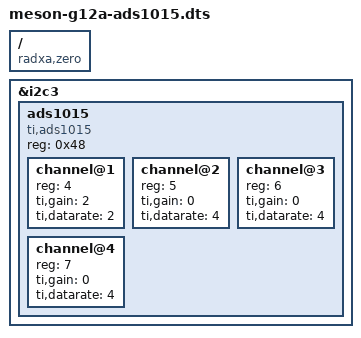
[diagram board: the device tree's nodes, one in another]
/dts-v1/;
/plugin/;

/ {
compatible = "radxa,zero", "amlogic,g12a";

/* ----------- ADS1015 ------------ */
        fragment@0 {
                target = <&i2c3>;
                __overlay__ {
                        #address-cells = <1>;
                        #size-cells = <0>;
                        status = "okay";
                        ads1015: ads1015 {
                                compatible = "ti,ads1015";
                                status = "okay";
                                #address-cells = <1>;
                                #size-cells = <0>;
                                #io-channel-cells = <1>;
                                reg = <0x48>;
                                channel@1 {
                                        reg = <4>;
                                        ti,gain = <2>;
                                        ti,datarate = <2>;
                                };
                                channel@2 {
                                        reg = <5>;
                                        ti,gain = <0>;
                                        ti,datarate = <4>;
                                };
                                channel@3 {
                                        reg = <6>;
                                        ti,gain = <0>;
                                        ti,datarate = <4>;
                                };
                                channel@4 {
                                        reg = <7>;
                                        ti,gain = <0>;
                                        ti,datarate = <4>;
                                };
                        };
                };
        };
};
